# HT32F1654 register map
Vendor: Holtek Semiconductor; Series: HT32F1xxx; File version: 1.0
This is the description for the Holtek HT32F1654
CPU: CM3 r2p0, little endian, VTOR, 4 interrupt priority bits, 69 interrupts
Registers are 32-bit, read-write, reset 0x0 unless marked. A register's access mark holds for its fields unless they carry their own. Offsets are from the block's base; lines under a group give offsets from that group; [hi:lo] are bit positions; {n}, {i} and the like mark numbered series; 'fields as' and 'values as' point back to an identical list; <NAME> marks a mode.

## Memory map
0x40000000 USART0 size 0x1000
0x40004000 SPI0 size 0x1000
0x40010000 ADC size 0x1000
0x40022000 AFIO size 0x1000
0x40024000 EXTI size 0x1000
0x4002C000 MCTM0 size 0x1000
0x4002D000 MCTM1 size 0x1000
0x40040000 USART1 size 0x1000
0x40043000 SCI size 0x1000
0x40044000 SPI1 size 0x1000
0x40048000 I2C0 size 0x1000
0x40049000 I2C1 size 0x1000
0x40068000 WDT size 0x1000
0x4006A000 PWRCU size 0x1000
0x4006A000 RTC size 0x1000
0x4006E000 GPTM0 size 0x1000
0x4006F000 GPTM1 size 0x1000
0x40076000 BFTM0 size 0x1000
0x40077000 BFTM1 size 0x1000
0x40080000 FMC size 0x1000
0x40088000 CKCU size 0x1000
0x40088100 RSTCU size 0x1000
0x40090000 PDMA size 0x1000
0x400A8000 USB blocks up to offset 0x4000
0x400B0000 GPIOA size 0x2000
0x400B2000 GPIOB size 0x2000
0x400B4000 GPIOC size 0x2000
0x400B6000 GPIOD size 0x2000

## Interrupts
16 CKCU
19 WDT
20 RTC
21 FMC
{n+24} EXTI{n} (EXTI) (n=0..15)
41 ADC
43 BRK (MCTM0)
44 UP (MCTM0)
45 TR_UP2 (MCTM0)
46 CC (MCTM0)
51 GPTM0
57 BFTM0
59 I2C0
61 SPI0
63 USART0
67 SCI
69 USB
{n+71} CH{n} (PDMA) (n=0..11)

## FMC
Base 0x40080000
0x00 TADR
  [31:0] TADB
0x04 WRDR
  [31:0] WRDB
0x0C OCMR
  [3:0] CMD
0x10 OPCR
  [4:1] OPM
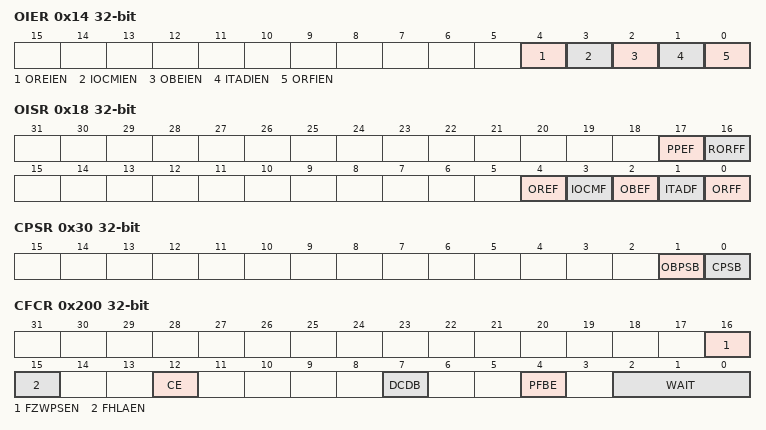
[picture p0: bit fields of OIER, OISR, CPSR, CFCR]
0x14 OIER
  [4] OREIEN, [3] IOCMIEN, [2] OBEIEN, [1] ITADIEN, [0] ORFIEN
0x18 OISR
  [17] PPEF, [16] RORFF, [4] OREF, [3] IOCMF, [2] OBEF, [1] ITADF, [0] ORFF
{0x20+4i} PPSR{i} (i=0..3)
  [31:0] PPSB
0x30 CPSR
  [1] OBPSB, [0] CPSB
0x100 VMCR
  [1:0] VMCB
0x200 CFCR
  [16] FZWPSEN, [15] FHLAEN, [12] CE, [7] DCDB, [4] PFBE, [2:0] WAIT
{0x300+4i} SBVT{i} (i=0..3)
  [31:0] SBVT

## PWRCU
Base 0x4006A000
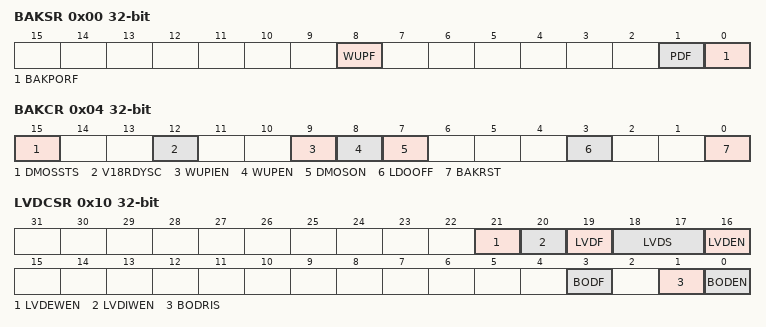
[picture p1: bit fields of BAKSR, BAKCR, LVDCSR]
0x00 BAKSR
  [8] WUPF, [1] PDF, [0] BAKPORF
0x04 BAKCR
  [15] DMOSSTS, [12] V18RDYSC, [9] WUPIEN, [8] WUPEN, [7] DMOSON, [3] LDOOFF, [0] BAKRST
0x08 BAKTEST
  [7:0] BAKTEST
0x0C HSIRCR
  [1:0] HSIRCBL
0x10 LVDCSR
  [21] LVDEWEN, [20] LVDIWEN, [19] LVDF, [18:17] LVDS, [16] LVDEN, [3] BODF, [1] BODRIS, [0] BODEN
{0x100+4i} BAKREG{i} (i=0..9)
  [31:0] BAKREG

## CKCU
Base 0x40088000
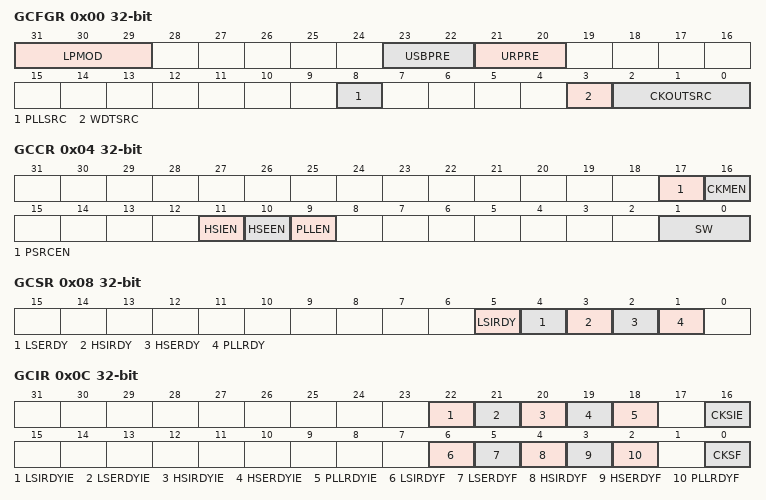
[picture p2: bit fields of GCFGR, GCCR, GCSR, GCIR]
0x00 GCFGR
  [31:29] LPMOD, [23:22] USBPRE, [21:20] URPRE, [8] PLLSRC, [3] WDTSRC, [2:0] CKOUTSRC
0x04 GCCR
  [17] PSRCEN, [16] CKMEN, [11] HSIEN, [10] HSEEN, [9] PLLEN, [1:0] SW
0x08 GCSR
  [5] LSIRDY, [4] LSERDY, [3] HSIRDY, [2] HSERDY, [1] PLLRDY
0x0C GCIR
  [22] LSIRDYIE, [21] LSERDYIE, [20] HSIRDYIE, [19] HSERDYIE, [18] PLLRDYIE, [16] CKSIE, [6] LSIRDYF, [5] LSERDYF, [4] HSIRDYF, [3] HSERDYF, [2] PLLRDYF, [0] CKSF
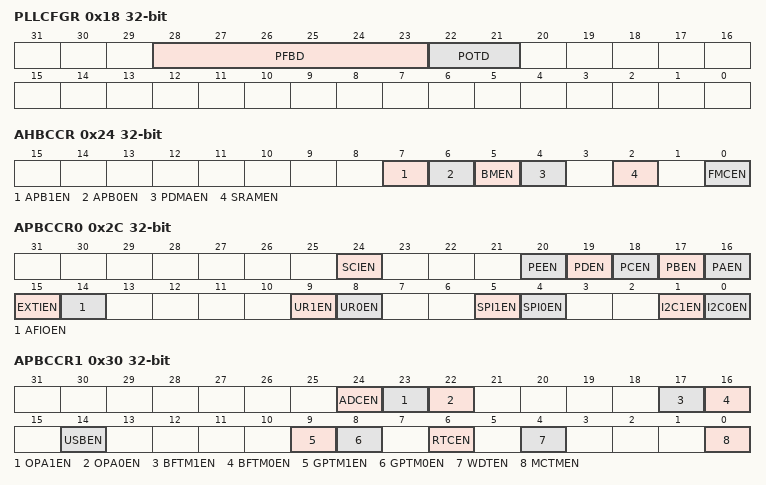
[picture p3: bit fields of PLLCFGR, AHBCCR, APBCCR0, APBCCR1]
0x18 PLLCFGR
  [28:23] PFBD, [22:21] POTD
0x1C PLLCR
  [31] PLLBPS
0x20 AHBCFGR
  [1:0] AHBPRE
0x24 AHBCCR
  [7] APB1EN, [6] APB0EN, [5] BMEN, [4] PDMAEN, [2] SRAMEN, [0] FMCEN
0x28 APBCFGR
  [18:16] ADCDIV
0x2C APBCCR0
  [24] SCIEN, [20] PEEN, [19] PDEN, [18] PCEN, [17] PBEN, [16] PAEN, [15] EXTIEN, [14] AFIOEN, [9] UR1EN, [8] UR0EN, [5] SPI1EN, [4] SPI0EN, [1] I2C1EN, [0] I2C0EN
0x30 APBCCR1
  [24] ADCEN, [23] OPA1EN, [22] OPA0EN, [17] BFTM1EN, [16] BFTM0EN, [14] USBEN, [9] GPTM1EN, [8] GPTM0EN, [6] RTCEN, [4] WDTEN, [0] MCTMEN
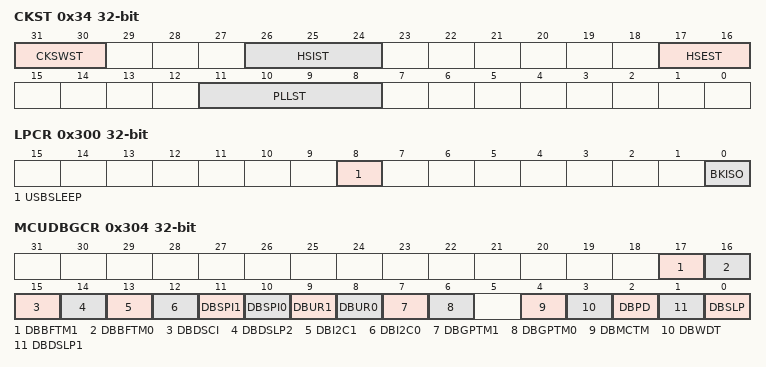
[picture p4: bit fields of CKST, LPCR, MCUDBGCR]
0x34 CKST
  [31:30] CKSWST, [26:24] HSIST, [17:16] HSEST, [11:8] PLLST
0x300 LPCR
  [8] USBSLEEP, [0] BKISO
0x304 MCUDBGCR
  [17] DBBFTM1, [16] DBBFTM0, [15] DBDSCI, [14] DBDSLP2, [13] DBI2C1, [12] DBI2C0, [11] DBSPI1, [10] DBSPI0, [9] DBUR1, [8] DBUR0, [7] DBGPTM1, [6] DBGPTM0, [4] DBMCTM, [3] DBWDT, [2] DBPD, [1] DBDSLP1, [0] DBSLP

## RSTCU
Base 0x40088100
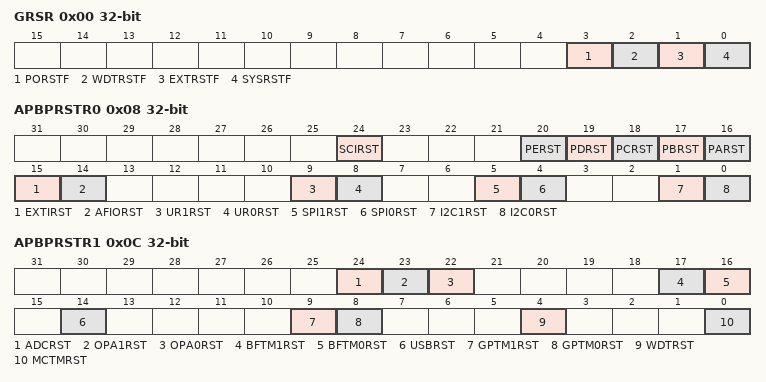
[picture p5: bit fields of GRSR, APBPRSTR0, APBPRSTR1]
0x00 GRSR
  [3] PORSTF, [2] WDTRSTF, [1] EXTRSTF, [0] SYSRSTF
0x04 AHBPRSTR
  [0] DMARST
0x08 APBPRSTR0
  [24] SCIRST, [20] PERST, [19] PDRST, [18] PCRST, [17] PBRST, [16] PARST, [15] EXTIRST, [14] AFIORST, [9] UR1RST, [8] UR0RST, [5] SPI1RST, [4] SPI0RST, [1] I2C1RST, [0] I2C0RST
0x0C APBPRSTR1
  [24] ADCRST, [23] OPA1RST, [22] OPA0RST, [17] BFTM1RST, [16] BFTM0RST, [14] USBRST, [9] GPTM1RST, [8] GPTM0RST, [4] WDTRST, [0] MCTMRST

## Notices in the file
Copyright (C) 2010 ARM Limited. All rights reserved.
ARM Limited (ARM) is supplying this SVD description for use with Cortex-M3
processor based microcontrollers.  This file and or content can be freely
distributed within development tools that are supporting such ARM based
processors.
THIS SOFTWARE IS PROVIDED "AS IS".  NO WARRANTIES, WHETHER EXPRESS, IMPLIED
OR STATUTORY, INCLUDING, BUT NOT LIMITED TO, IMPLIED WARRANTIES OF
MERCHANTABILITY AND FITNESS FOR A PARTICULAR PURPOSE APPLY TO THIS SOFTWARE.
ARM SHALL NOT, IN ANY CIRCUMSTANCES, BE LIABLE FOR SPECIAL, INCIDENTAL, OR
CONSEQUENTIAL DAMAGES, FOR ANY REASON WHATSOEVER.
